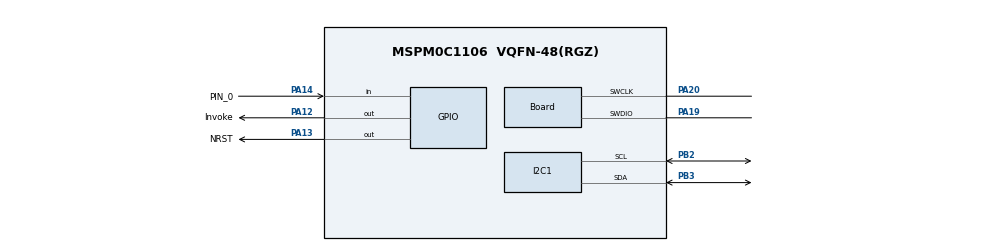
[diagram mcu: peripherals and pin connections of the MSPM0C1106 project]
//@cliArgs --device "MSPM0C1105_C1106" --package "VQFN-48(RGZ)" --part "Default"
//@v2CliArgs --device "MSPM0C1106" --package "VQFN-48(RGZ)"
// @cliArgs --board /ti/boards/LP_MSPM0C1106 --rtos nortos

/**
 * Import the modules used in this configuration.
 */
const GPIO   = scripting.addModule("/ti/driverlib/GPIO", {}, false);
const GPIO1  = GPIO.addInstance();
const GPIO2  = GPIO.addInstance();
const GPIO3  = GPIO.addInstance();
const I2C    = scripting.addModule("/ti/driverlib/I2C", {}, false);
const I2C1   = I2C.addInstance();
const SYSCTL = scripting.addModule("/ti/driverlib/SYSCTL");

/**
 * Write custom configuration values to the imported modules.
 */
GPIO1.$name                              = "GPIO_Button";
GPIO1.associatedPins[0].$name            = "PIN_0";
GPIO1.associatedPins[0].direction        = "INPUT";
GPIO1.associatedPins[0].internalResistor = "PULL_UP";
GPIO1.associatedPins[0].assignedPort     = "PORTA";
GPIO1.associatedPins[0].pin.$assign      = "PA14";

const Board                       = scripting.addModule("/ti/driverlib/Board", {}, false);
Board.peripheral.$assign          = "DEBUGSS";
Board.peripheral.swclkPin.$assign = "PA20";
Board.peripheral.swdioPin.$assign = "PA19";

GPIO2.$name                          = "GPIO_BSL";
GPIO2.associatedPins.create(2);
GPIO2.associatedPins[0].$name        = "NRST";
GPIO2.associatedPins[0].initialValue = "SET";
GPIO2.associatedPins[0].assignedPort = "PORTA";
GPIO2.associatedPins[0].assignedPin  = "13";
GPIO2.associatedPins[0].pin.$assign  = "PA13";
GPIO2.associatedPins[1].$name        = "Invoke";
GPIO2.associatedPins[1].assignedPort = "PORTA";
GPIO2.associatedPins[1].assignedPin  = "12";
GPIO2.associatedPins[1].pin.$assign  = "PA12";

GPIO3.$name                          = "GPIO_LED";
GPIO3.associatedPins[0].assignedPort = "PORTA";
GPIO3.associatedPins[0].initialValue = "SET";
GPIO3.associatedPins[0].$name        = "Error";
GPIO3.associatedPins[0].assignedPin  = "0";

I2C1.$name                         = "I2C_0";
I2C1.basicEnableController         = true;
I2C1.peripheral.$assign            = "I2C1";
I2C1.peripheral.sdaPin.$assign     = "PB3";
I2C1.peripheral.sclPin.$assign     = "PB2";
I2C1.sdaPinConfig.internalResistor = "PULL_UP";
I2C1.sdaPinConfig.enableConfig     = true;
I2C1.sclPinConfig.internalResistor = "PULL_UP";
I2C1.sclPinConfig.enableConfig     = true;

SYSCTL.peripheral.$assign = "SYSCTL";

const ProjectConfig              = scripting.addModule("/ti/project_config/ProjectConfig", {}, false);
ProjectConfig.migrationCondition = true;
